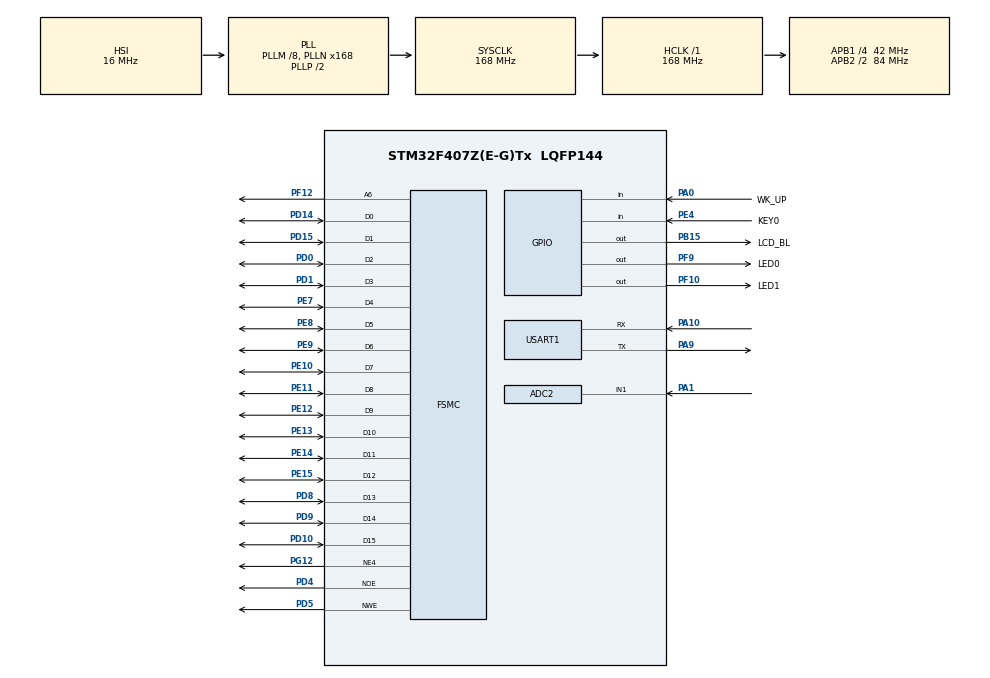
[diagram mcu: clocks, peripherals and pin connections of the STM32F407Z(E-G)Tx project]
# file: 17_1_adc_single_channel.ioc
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ADC2.Channel-0\#ChannelRegularConversion=ADC_CHANNEL_1
ADC2.EnableAnalogWatchDog=false
ADC2.InjNumberOfConversion=0
ADC2.NbrOfConversionFlag=1
ADC2.Rank-0\#ChannelRegularConversion=1
ADC2.SamplingTime-0\#ChannelRegularConversion=ADC_SAMPLETIME_480CYCLES
FSMC.AddressSetupTime1=15
FSMC.BusTurnAroundDuration1=0
FSMC.DataSetupTime1=60
FSMC.ExtendedAddressSetupTime1=9
FSMC.ExtendedBusTurnAroundDuration1=0
FSMC.ExtendedDataSetupTime1=9
FSMC.ExtendedMode1=FSMC_EXTENDED_MODE_ENABLE
Mcu.Family=STM32F4
Mcu.Name=STM32F407Z(E-G)Tx
Mcu.Package=LQFP144
NVIC.PriorityGroup=NVIC_PRIORITYGROUP_2
NVIC.USART1_IRQn=true\:2\:2\:true\:false\:true\:true\:true\:true
PA0-WKUP.GPIO_Label=WK_UP
PA0-WKUP.GPIO_PuPd=GPIO_PULLDOWN
PA0-WKUP.Signal=GPIO_Input
PA1.Signal=ADCx_IN1
PA10.GPIO_PuPd=GPIO_PULLUP
PA10.Mode=Asynchronous
PA10.Signal=USART1_RX
PA13.Mode=Serial_Wire
PA13.Signal=SYS_JTMS-SWDIO
PA14.Mode=Serial_Wire
PA14.Signal=SYS_JTCK-SWCLK
PA9.GPIO_PuPd=GPIO_PULLUP
PA9.Mode=Asynchronous
PA9.Signal=USART1_TX
PB15.GPIO_Label=LCD_BL
PB15.GPIO_PuPd=GPIO_PULLUP
PB15.GPIO_Speed=GPIO_SPEED_FREQ_VERY_HIGH
PB15.PinState=GPIO_PIN_SET
PB15.Signal=GPIO_Output
PC14-OSC32_IN.Mode=LSE-External-Oscillator
PC14-OSC32_IN.Signal=RCC_OSC32_IN
PC15-OSC32_OUT.Mode=LSE-External-Oscillator
PC15-OSC32_OUT.Signal=RCC_OSC32_OUT
PD0.Signal=FSMC_D2_DA2
PD1.Signal=FSMC_D3_DA3
PD10.Signal=FSMC_D15_DA15
PD14.Signal=FSMC_D0_DA0
PD15.Signal=FSMC_D1_DA1
PD4.Signal=FSMC_NOE
PD5.Signal=FSMC_NWE
PD8.Signal=FSMC_D13_DA13
PD9.Signal=FSMC_D14_DA14
PE10.Signal=FSMC_D7_DA7
PE11.Signal=FSMC_D8_DA8
PE12.Signal=FSMC_D9_DA9
PE13.Signal=FSMC_D10_DA10
PE14.Signal=FSMC_D11_DA11
PE15.Signal=FSMC_D12_DA12
PE4.GPIO_Label=KEY0
PE4.GPIO_PuPd=GPIO_PULLDOWN
PE4.Signal=GPIO_Input
PE7.Signal=FSMC_D4_DA4
PE8.Signal=FSMC_D5_DA5
PE9.Signal=FSMC_D6_DA6
PF10.GPIO_Label=LED1
PF10.GPIO_PuPd=GPIO_PULLDOWN
PF10.GPIO_Speed=GPIO_SPEED_FREQ_VERY_HIGH
PF10.PinState=GPIO_PIN_SET
PF10.Signal=GPIO_Output
PF12.Signal=FSMC_A6
PF9.GPIO_Label=LED0
PF9.GPIO_PuPd=GPIO_PULLDOWN
PF9.GPIO_Speed=GPIO_SPEED_FREQ_VERY_HIGH
PF9.PinState=GPIO_PIN_SET
PF9.Signal=GPIO_Output
PG12.Mode=NorPsramChipSelect4_1
PG12.Signal=FSMC_NE4
PH0-OSC_IN.Mode=HSE-External-Oscillator
PH0-OSC_IN.Signal=RCC_OSC_IN
PH1-OSC_OUT.Mode=HSE-External-Oscillator
PH1-OSC_OUT.Signal=RCC_OSC_OUT
ProjectManager.HeapSize=0x200
ProjectManager.StackSize=0x400
ProjectManager.TargetToolchain=STM32CubeIDE
RCC.48MHZClocksFreq_Value=84000000
RCC.AHBFreq_Value=168000000
RCC.APB1CLKDivider=RCC_HCLK_DIV4
RCC.APB1Freq_Value=42000000
RCC.APB1TimFreq_Value=84000000
RCC.APB2CLKDivider=RCC_HCLK_DIV2
RCC.APB2Freq_Value=84000000
RCC.APB2TimFreq_Value=168000000
RCC.CortexFreq_Value=168000000
RCC.HCLKFreq_Value=168000000
RCC.HSE_VALUE=25000000
RCC.HSI_VALUE=16000000
RCC.PLLM=8
RCC.PLLN=168
RCC.SYSCLKFreq_VALUE=168000000
RCC.SYSCLKSource=RCC_SYSCLKSOURCE_PLLCLK
RCC.VCOOutputFreq_Value=336000000
SH.ADCx_IN1.0=ADC2_IN1,IN1
SH.FSMC_A6.0=FSMC_A6,A6_1
SH.FSMC_D0_DA0.0=FSMC_D0,16b-d1
SH.FSMC_D10_DA10.0=FSMC_D10,16b-d1
SH.FSMC_D11_DA11.0=FSMC_D11,16b-d1
SH.FSMC_D12_DA12.0=FSMC_D12,16b-d1
SH.FSMC_D13_DA13.0=FSMC_D13,16b-d1
SH.FSMC_D14_DA14.0=FSMC_D14,16b-d1
SH.FSMC_D15_DA15.0=FSMC_D15,16b-d1
SH.FSMC_D1_DA1.0=FSMC_D1,16b-d1
SH.FSMC_D2_DA2.0=FSMC_D2,16b-d1
SH.FSMC_D3_DA3.0=FSMC_D3,16b-d1
SH.FSMC_D4_DA4.0=FSMC_D4,16b-d1
SH.FSMC_D5_DA5.0=FSMC_D5,16b-d1
SH.FSMC_D6_DA6.0=FSMC_D6,16b-d1
SH.FSMC_D7_DA7.0=FSMC_D7,16b-d1
SH.FSMC_D8_DA8.0=FSMC_D8,16b-d1
SH.FSMC_D9_DA9.0=FSMC_D9,16b-d1
SH.FSMC_NOE.0=FSMC_NOE,Lcd1
SH.FSMC_NWE.0=FSMC_NWE,Lcd1
USART1.VirtualMode=VM_ASYNC
board=custom

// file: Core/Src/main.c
/* USER CODE BEGIN Header */
/**
 ****************************************************************************************************
 * @file        main.c
 * @author      ALIENTEK
 * @brief       adc_single_channel code
 * @license     Copyright (C) 2020-2032, ALIENTEK
 ****************************************************************************************************
 * @attention
 *
 * platform     : ALIENTEK M144-STM32F407 board
 * website      : https://www.alientek.com
 * forum        : http://www.openedv.com/forum.php
 *
 * change logs  :
 * version    data    notes
 * V1.0     20240410  the first version
 *
 ****************************************************************************************************
 */
/* USER CODE END Header */
#include "main.h"
#include "adc.h"
#include "usart.h"
#include "gpio.h"
#include "fsmc.h"

/* USER CODE BEGIN Includes */
#include "../../BSP/LED/led.h"
#include "../../BSP/KEY/key.h"
#include "../../BSP/LCD/lcd.h"
#include "../../SYSTEM/delay/delay.h"
/* USER CODE END Includes */

void SystemClock_Config(void);

int main(void)
{
  /* USER CODE BEGIN 1 */
    uint16_t adc_result;
    uint16_t voltage;
  /* USER CODE END 1 */

  /* MCU Configuration--------------------------------------------------------*/

  /* Reset of all peripherals, Initializes the Flash interface and the Systick. */
  HAL_Init();

  /* Configure the system clock */
  SystemClock_Config();

  /* USER CODE BEGIN SysInit */
  delay_init(168);
  /* USER CODE END SysInit */

  /* Initialize all configured peripherals */
  MX_GPIO_Init();
  MX_USART1_UART_Init();
  MX_FSMC_Init();
  MX_ADC2_Init();
  /* USER CODE BEGIN 2 */

  lcd_init();
  lcd_show_string(30, 50, 200, 16, 16, "STM32", RED);
  lcd_show_string(30, 70, 200, 16, 16, "ADC TEST", RED);
  lcd_show_string(30, 90, 200, 16, 16, "ATOM@ALIENTEK", RED);

  lcd_show_string(30, 110, 200, 16, 16, "ADC1_CH1_VAL:0", BLUE);
  lcd_show_string(30, 130, 200, 16, 16, "ADC1_CH1_VOL:0.000V", BLUE);

  /* USER CODE END 2 */

  /* Infinite loop */
  while (1)
  {

      adc_result = adc_get_result_average(ADC_CHANNEL_1, 10);      /* The result of ADC channel 10 conversion and mean filtering is obtained */
      lcd_show_xnum(134, 110, adc_result, 5, 16, 0, BLUE);

      voltage = (adc_result * 3300) / 4095;                       /* Calculate the actual voltage value (1000x enlargement) */
      lcd_show_xnum(134, 130, voltage / 1000, 1, 16, 0, BLUE);
      lcd_show_xnum(150, 130, voltage % 1000, 3, 16, 0x80, BLUE);

      LED0_TOGGLE();
      HAL_Delay(100);

  }
}

void SystemClock_Config(void)
{
  RCC_OscInitTypeDef RCC_OscInitStruct = {0};
  RCC_ClkInitTypeDef RCC_ClkInitStruct = {0};

  /** Configure the main internal regulator output voltage
  */
  __HAL_RCC_PWR_CLK_ENABLE();
  __HAL_PWR_VOLTAGESCALING_CONFIG(PWR_REGULATOR_VOLTAGE_SCALE1);

  /** Initializes the RCC Oscillators according to the specified parameters
  * in the RCC_OscInitTypeDef structure.
  */
  RCC_OscInitStruct.OscillatorType = RCC_OSCILLATORTYPE_HSI;
  RCC_OscInitStruct.HSIState = RCC_HSI_ON;
  RCC_OscInitStruct.HSICalibrationValue = RCC_HSICALIBRATION_DEFAULT;
  RCC_OscInitStruct.PLL.PLLState = RCC_PLL_ON;
  RCC_OscInitStruct.PLL.PLLSource = RCC_PLLSOURCE_HSI;
  RCC_OscInitStruct.PLL.PLLM = 8;
  RCC_OscInitStruct.PLL.PLLN = 168;
  RCC_OscInitStruct.PLL.PLLP = RCC_PLLP_DIV2;
  RCC_OscInitStruct.PLL.PLLQ = 4;
  if (HAL_RCC_OscConfig(&RCC_OscInitStruct) != HAL_OK)
  {
    Error_Handler();
  }

  /** Initializes the CPU, AHB and APB buses clocks
  */
  RCC_ClkInitStruct.ClockType = RCC_CLOCKTYPE_HCLK|RCC_CLOCKTYPE_SYSCLK
                              |RCC_CLOCKTYPE_PCLK1|RCC_CLOCKTYPE_PCLK2;
  RCC_ClkInitStruct.SYSCLKSource = RCC_SYSCLKSOURCE_PLLCLK;
  RCC_ClkInitStruct.AHBCLKDivider = RCC_SYSCLK_DIV1;
  RCC_ClkInitStruct.APB1CLKDivider = RCC_HCLK_DIV4;
  RCC_ClkInitStruct.APB2CLKDivider = RCC_HCLK_DIV2;

  if (HAL_RCC_ClockConfig(&RCC_ClkInitStruct, FLASH_LATENCY_5) != HAL_OK)
  {
    Error_Handler();
  }
}

void Error_Handler(void)
{
  __disable_irq();
  while (1)
  {
  }
}
